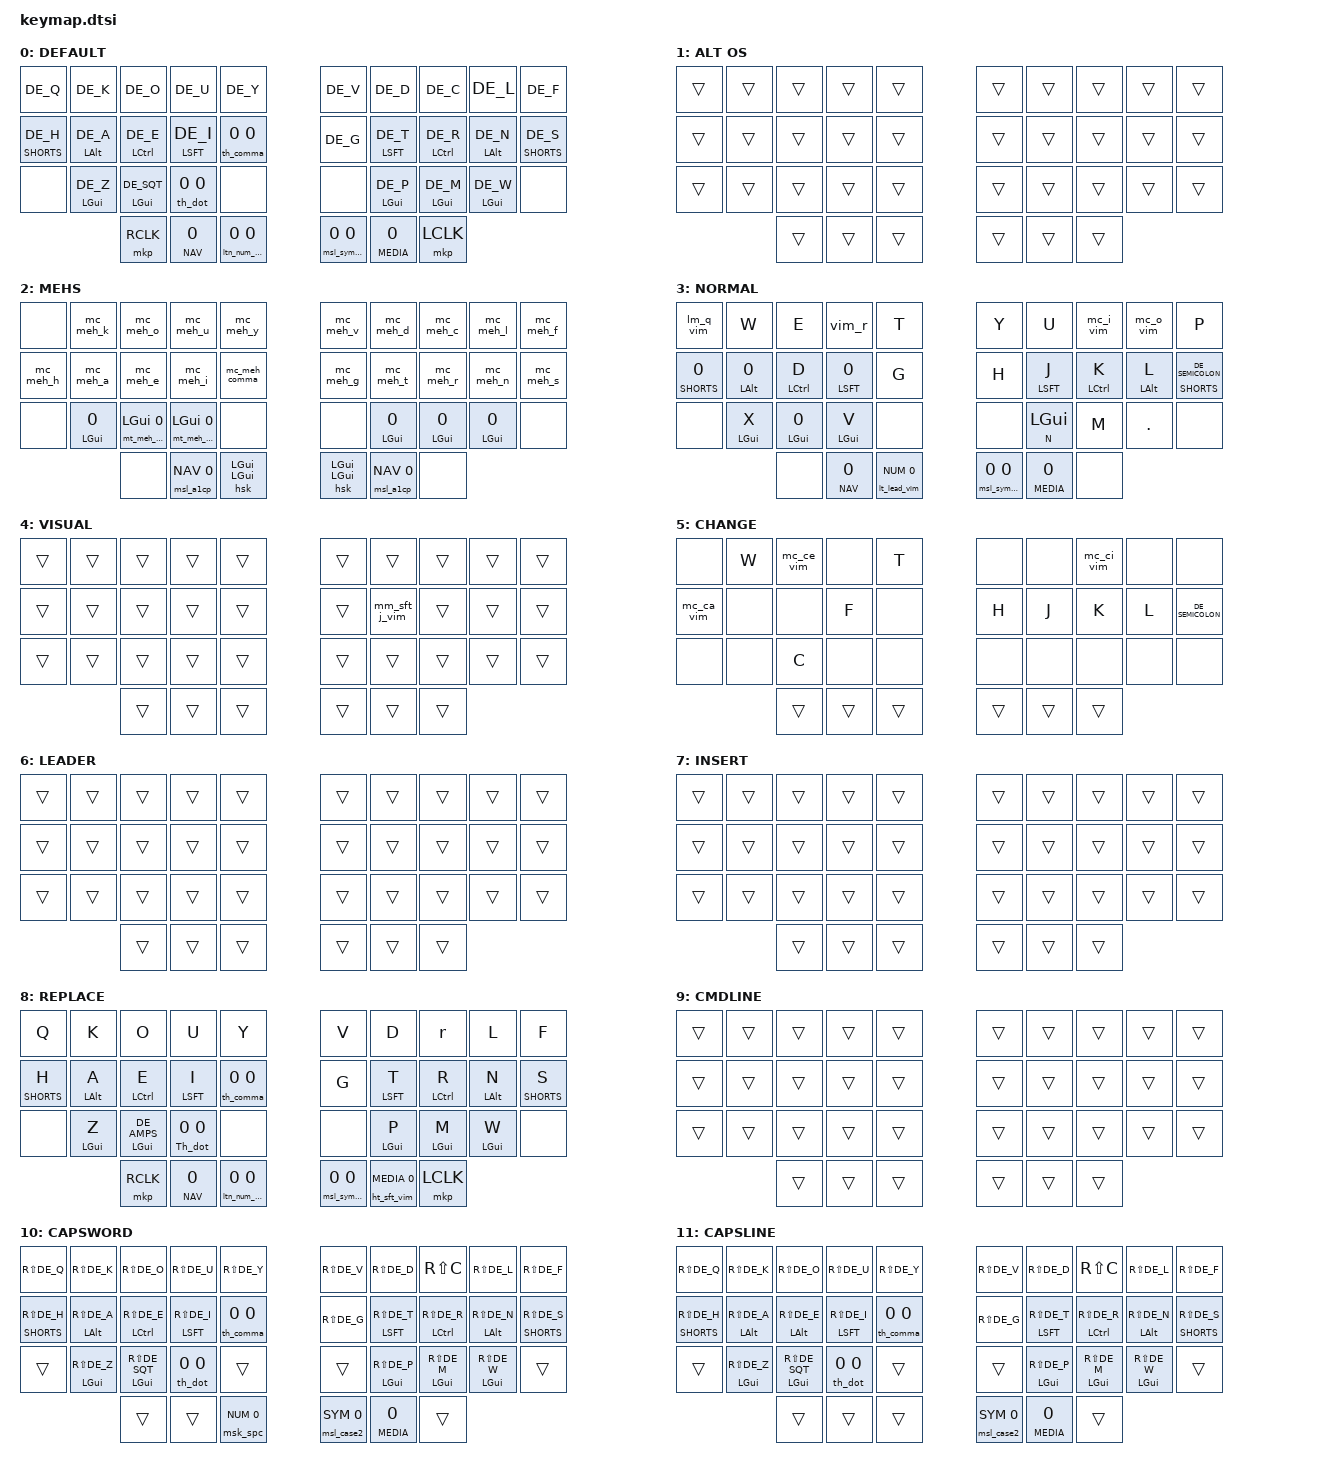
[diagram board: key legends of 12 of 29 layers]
/*
*
* Copyright (c) 2022 Rafael Romão
* SPDX-License-Identifier: MIT
*
*/

#include "includes.h"

/ {
        keymap {
                compatible = "zmk,keymap";

                default_layer {
                     display-name = "DEFAULT";
                     bindings = <
   &kp DE_Q            &kp DE_K            &kp DE_O            &kp DE_U            &kp DE_Y            &kp DE_V            &kp DE_D            &kp DE_C            &kp DE_L           &kp DE_F
   &lt SHORTS DE_H     &mt LALT DE_A       &mt LCTL DE_E       &mt LSFT DE_I       &th_comma 0 0       &kp DE_G            &mt LSFT DE_T       &mt LCTL DE_R       &mt LALT DE_N      &lt SHORTS DE_S
   &none               &mt LGUI DE_Z       &mt LGUI DE_SQT     &th_dot 0 0         &none               &none               &mt LGUI DE_P       &mt LGUI DE_M       &mt LGUI DE_W      &none
                                           &mkp RCLK           &ht_repeat NAV 0    &ltn_num_spc 0 0    &msl_sym_a2 0 0     &ht_shift MEDIA 0   &mkp LCLK
                        >;
                };

                alt_os_layer {
                     display-name = "ALT OS";
                     bindings = <
   &trans              &trans              &trans              &trans              &trans              &trans              &trans              &trans              &trans              &trans
   &trans              &trans              &trans              &trans              &trans              &trans              &trans              &trans              &trans              &trans
   &trans              &trans              &trans              &trans              &trans              &trans              &trans              &trans              &trans              &trans
                                           &trans              &trans              &trans              &trans              &trans              &trans
                        >;
                };


                mehs_layer {
                     display-name = "MEHS";
                     bindings = <
   &none              &mc_meh_k            &mc_meh_o           &mc_meh_u           &mc_meh_y           &mc_meh_v           &mc_meh_d           &mc_meh_c           &mc_meh_l           &mc_meh_f
   &mc_meh_h          &mc_meh_a            &mc_meh_e           &mc_meh_i           &mc_meh_comma       &mc_meh_g           &mc_meh_t           &mc_meh_r           &mc_meh_n           &mc_meh_s
   &none              &mt_meh_z LGUI 0     &mt_meh_sqt LGUI 0  &mt_meh_dot LGUI 0  &none               &none               &mt_meh_p LGUI 0    &mt_meh_m LGUI 0    &mt_meh_w LGUI 0    &none
                                           &none               &msl_a1cp NAV 0     &hsk LGUI LGUI      &hsk LGUI LGUI      &msl_a1cp NAV 0     &none
                        >;
                };


                vim_normal_layer {
                     display-name = "NORMAL";
                     bindings = <
   &lm_q_vim           &kp W               &kp E               &vim_r              &kp T               &kp Y               &kp U               &mc_i_vim           &mc_o_vim           &kp P
   &lt_a_vim SHORTS 0  &mt_s_vim LALT 0    &mt LCTL D          &mt_f_vim LSFT 0    &kp G               &kp H               &mt LSFT J          &mt LCTL K          &mt LALT L          &lt SHORTS DE_SEMICOLON
   &none               &mt LGUI X          &mt_c_vim LGUI 0    &mt LGUI V          &none               &none               &mt N LGUI 0        &kp M               &kp DOT             &none
                                           &none               &ht_repeat NAV 0    &lt_lead_vim NUM 0  &msl_sym_a2 0 0     &ht_shift MEDIA 0   &none
                        >;
                };

                vim_visual_layer {
                     display-name = "VISUAL";
                     bindings = <
   &trans              &trans              &trans              &trans              &trans              &trans              &trans              &trans              &trans              &trans
   &trans              &trans              &trans              &trans              &trans              &trans              &mm_sft_j_vim       &trans              &trans              &trans
   &trans              &trans              &trans              &trans              &trans              &trans              &trans              &trans              &trans              &trans
                                           &trans              &trans              &trans              &trans              &trans              &trans
                        >;
                };

                vim_change_layer {
                     display-name = "CHANGE";
                     bindings = <
   &none               &kp W               &mc_ce_vim          &none               &kp T               &none               &none               &mc_ci_vim          &none               &none
   &mc_ca_vim          &none               &none               &kp F               &none               &kp H               &kp J               &kp K               &kp L               &kp DE_SEMICOLON
   &none               &none               &kp C               &none               &none               &none               &none               &none               &none               &none
                                           &trans              &trans              &trans              &trans              &trans              &trans
                        >;
                };

                vim_leader_layer {
                     display-name = "LEADER";
                     bindings = <
   &trans              &trans              &trans              &trans              &trans              &trans              &trans              &trans              &trans              &trans
   &trans              &trans              &trans              &trans              &trans              &trans              &trans              &trans              &trans              &trans
   &trans              &trans              &trans              &trans              &trans              &trans              &trans              &trans              &trans              &trans
                                           &trans              &trans              &trans              &trans              &trans              &trans
                        >;
                };

                vim_insert_layer {
                     display-name = "INSERT";
                     bindings = <
   &trans              &trans              &trans              &trans              &trans              &trans              &trans              &trans              &trans              &trans
   &trans              &trans              &trans              &trans              &trans              &trans              &trans              &trans              &trans              &trans
   &trans              &trans              &trans              &trans              &trans              &trans              &trans              &trans              &trans              &trans
                                           &trans              &trans              &trans              &trans              &trans              &trans
                        >;
                };

                vim_replace_layer {
                     display-name = "REPLACE";
                     bindings = <
   &kp Q               &kp K               &kp O               &kp U               &kp Y               &kp V               &kp D               &kp r               &kp L               &kp F
   &lt SHORTS H        &mt LALT A          &mt LCTL E          &mt LSFT I          &th_comma 0 0       &kp G               &mt LSFT T          &mt LCTL R          &mt LALT N          &lt SHORTS S
   &none               &mt LGUI Z          &mt LGUI DE_AMPS    &Th_dot 0 0         &none               &none               &mt LGUI P          &mt LGUI M          &mt LGUI W          &none
                                           &mkp RCLK           &ht_repeat NAV 0    &ltn_num_spc 0 0    &msl_sym_a2 0 0     &ht_sft_vim MEDIA 0 &mkp LCLK
                        >;
                };

                vim_cmdline_layer {
                     display-name = "CMDLINE";
                     bindings = <
   &trans              &trans              &trans              &trans              &trans              &trans              &trans              &trans              &trans              &trans
   &trans              &trans              &trans              &trans              &trans              &trans              &trans              &trans              &trans              &trans
   &trans              &trans              &trans              &trans              &trans              &trans              &trans              &trans              &trans              &trans
                                           &trans              &trans              &trans              &trans              &trans              &trans
                        >;
                };


                capsword_layer {
                     display-name = "CAPSWORD";
                     bindings = <
   &kp RS(DE_Q)        &kp RS(DE_K)        &kp RS(DE_O)        &kp RS(DE_U)        &kp RS(DE_Y)        &kp RS(DE_V)        &kp RS(DE_D)        &kp RS(C)           &kp RS(DE_L)        &kp RS(DE_F)
   &lt SHORTS RS(DE_H) &mt LALT RS(DE_A)   &mt LCTL RS(DE_E)   &mt LSFT RS(DE_I)   &th_comma 0 0       &kp RS(DE_G)        &mt LSFT RS(DE_T)   &mt LCTL RS(DE_R)   &mt LALT RS(DE_N)   &lt SHORTS RS(DE_S)
   &trans              &mt LGUI RS(DE_Z)   &mt LGUI RS(DE_SQT) &th_dot 0 0         &trans              &trans              &mt LGUI RS(DE_P)   &mt LGUI RS(DE_M)   &mt LGUI RS(DE_W)   &trans
                                           &trans              &trans              &msk_spc NUM 0      &msl_case2 SYM 0    &lt_cancel MEDIA 0  &trans
                        >;
                };
                capsline_layer {
                     display-name = "CAPSLINE";
                     bindings = <
   &kp RS(DE_Q)        &kp RS(DE_K)        &kp RS(DE_O)        &kp RS(DE_U)        &kp RS(DE_Y)        &kp RS(DE_V)        &kp RS(DE_D)        &kp RS(C)           &kp RS(DE_L)        &kp RS(DE_F)
   &lt SHORTS RS(DE_H) &mt LALT RS(DE_A)   &mt LALT RS(DE_E)   &mt LSFT RS(DE_I)   &th_comma 0 0       &kp RS(DE_G)        &mt LSFT RS(DE_T)   &mt LCTL RS(DE_R)   &mt LALT RS(DE_N)   &lt SHORTS RS(DE_S)
   &trans              &mt LGUI RS(DE_Z)   &mt LGUI RS(DE_SQT) &th_dot 0 0         &trans              &trans              &mt LGUI RS(DE_P)   &mt LGUI RS(DE_M)   &mt LGUI RS(DE_W)   &trans
                                           &trans              &trans              &trans              &msl_case2 SYM 0    &lt_cancel MEDIA 0  &trans
                        >;
                };

                alpha2_layer {
                     display-name = "ALPHA2";
                     bindings = <
   &none               &none               &kp DE_O_UMLAUT     &kp DE_U_UMLAUT     &none               &none               &kp DE_SZ           &kp DE_SZ           &none               &none
   &none               &kp DE_A_UMLAUT     &kp DE_A_UMLAUT     &kp DE_O_UMLAUT     &none               &none               &kp DE_B            &kp DE_J            &none               &none
   &none               &none               &kp DE_X            &kp DE_X            &none               &none               &none               &none               &none               &none
                                           &none               &mc_sqo             &kp DE_UNDER        &kp DE_SPACE        &mc_sqo             &none
                        >;
                };

                numbers_layer {
                     display-name = "NUMBERS";
                     bindings = <
   &none               &th_lbrc 0 0        &th_rbrc 0 0        &kp DE_BSLH         &none               &none               &mc_n7              &mc_n8              &mc_n9              &none
   &lt_deg FUN 0       &th_lpar 0 0        &th_rpar 0 0        &kp DE_AMPS         &none               &none               &mc_n4              &mc_n5              &mc_n6              &kp DE_DOT
   &none               &th_lbkt 0 0        &th_rbkt 0 0        &kp DE_PIPE         &none               &none               &mc_n1              &mc_n2              &mc_n3              &none
                                           &none               &trans              &trans              &hlt SYM SPACE      &lt_n0 MEDIA 0      &none 
                        >;
                };
                symbols_layer {
                     display-name = "SYMBOLS";
                     bindings = <
   &none               &mc_tilde           &kp DE_HASH         &th_sqo 0 0         &none               &none               &th_perc 0 0        &th_eql 0 0         &th_colon_vim 0 0   &none
   &kp DE_AT           &th_caret_z 0 0     &kp DE_DOLLAR       &th_dqo 0 0         &none               &none               &th_qmark 0 0       &kp DE_MINUS        &kp DE_PLUS         &lt MACROS DE_COMMA
   &none               &mc_lt              &mc_gt              &th_bti 0 0         &none               &none               &th_excl 0 0        &vim_slash          &kp DE_STAR         &none
                                           &none               &trans              &hlt NUM_CP SPACE   &none               &trans              &none
                        >;
                };

                sentence_case_layer {
                     display-name = "SENTENCE CASE";
                     bindings = <
   &kp LS(DE_Q)        &kp LS(DE_K)        &kp LS(DE_O)        &kp LS(DE_U)        &kp LS(DE_Y)        &kp LS(DE_V)        &kp LS(DE_D)        &kp LS(DE_C)        &kp LS(DE_L)        &kp LS(DE_F)
   &kp LS(DE_H)        &mt LALT LS(DE_A)   &mt LCTL LS(DE_E)   &mt LSFT LS(DE_I)   &th_comma           &kp LS(DE_G)        &mt LSFT LS(DE_T)   &mt LCTL LS(DE_R)   &mt LALT LS(DE_N)   &kp LS(DE_S)
   &none               &mt LGUI LS(DE_Z)   &mt LGUI LS(DE_SQT) &th_dot 0 0         &none               &none               &mt LGUI LS(DE_P)   &mt LGUI LS(DE_M)   &mt LGUI LS(DE_W)   &trans
                                           &trans              &trans              &trans              &lt_sft_a2 SYM_CP 0 &trans              &trans
                        >;
                };

                shifted_alpha2_layer {
                     display-name = "SHIFTED ALPHA2";
                     bindings = <
   &none               &none               &kp LS(DE_O_UMLAUT) &kp LS(DE_U_UMLAUT) &none               &none               &kp LS(DE_SZ)       &none               &none               &none
   &none               &kp LS(DE_A_UMLAUT) &kp LS(DE_A_UMLAUT) &kp LS(DE_O_UMLAUT) &none               &none               &kp LS(DE_B)        &kp LS(DE_J)        &none               &none
   &none               &none               &none               &kp LS(DE_X)        &none               &none               &none               &none               &none               &none
                                           &none               &mc_sqo             &trans              &kp SPACE           &mc_sqo             &none 
                        >;
                };
                case_alpha2_layer {
                     display-name = "CASE ALPHA2";
                     bindings = <
   &none               &kp RS(Q)           &kp RS(DE_O_UMLAUT) &kp RS(DE_U_UMLAUT) &none               &none               &ac_ocir_c          &ac_oacu_c          &ac_uacu_c          &none
   &none               &kp RS(DE_A_UMLAUT) &kp RS(DE_SHARP_S)  &kp RS(DE_X)        &none               &none               &ac_atil_c          &ac_aacu_c          &ac_eacu_c          &ac_iacu_c
   &none               &none               &none               &reversed_magic_c   &none               &none               &ac_otil_c          &ac_acir_c          &ac_ecir_c          &none
                                           &none               &mc_sqo             &kp DE_UNDER        &kp SPACE           &mc_sqo             &none
                        >;
                };

                shortcuts_layer {
                     display-name = "SHORTCUTS";
                     bindings = <
   &none              &mc_calc             &mc_files           &mc_browser         &none               &none               &mc_ai              &mc_editor          &mc_activities      &none
   &mc_leader         &lt_zoom_out TOGS 0  &mc_zoom_in         &mc_new             &none               &none               &tc_num_word        &mc_containers      &lt_emoji TOGS 0    &mc_leader
   &none              &mc_close            &mc_refresh         &mc_reopen          &none               &none               &mc_screenshot      &mc_notes           &mc_term            &none
                                           &none               &mo TEXT            &lt FUN SPACE       &lt MACROS SPACE    &mo TEXT            &none 
                        >;
                };
                toggles_layer {
                     display-name = "TOGGLES";
                     bindings = <
   &none              &none                &bt BT_SEL 0        &bt BT_CLR          &none               &none               &to NAV             &to FUN             &none               &none
   &none              &none                &bt BT_PRV          &bt BT_NXT          &none               &none               &to NUM             &to MEDIA           &none               &none
   &none              &bootloader          &tog_off ALT_OS     &to ALT_OS          &none               &none               &to VIM_NORMAL      &to MEHS            &bootloader         &none
                                           &none               &kp CAPS            &kp KP_NUM          &mc_lock            &mc_sleep           &none
                        >;
                };

                secondary_alternate_repeat_layer {
                     display-name = "ALT REP 2";
                     bindings = <
   &trans              &trans              &trans              &trans              &trans              &trans              &trans              &trans              &trans              &trans
   &trans              &trans              &trans              &trans              &trans              &trans              &trans              &trans              &trans              &trans
   &trans              &trans              &trans              &trans              &trans              &trans              &trans              &trans              &trans              &trans
                                           &trans              &ht_alt_rep NAV 0   &trans              &trans              &trans              &trans
                        >;
                };

                navigation_layer {
                     display-name = "NAVIGATION";
                     bindings = <
   &none               &mc_swapper         &mc_tabs            &mc_launcher        &none               &none               &kp TAB             &lm_ent_vim         &lm_esc_vim         &none
   &lt_system TEXT 0   &mod_num LALT LALT  &mod_num LCTL LCTL  &mod_num LSFT LSFT  &none               &none               &kp LEFT            &kp DOWN            &kp UP              &kp RIGHT
   &none               &mod_num LGUI LGUI  &mod_num LGUI LGUI  &mod_num LGUI LGUI  &none               &none               &kp DEL             &kp HOME            &kp END             &none
                                           &none               &trans              &none               &hlt SYM_CP SPACE   &lt MEDIA INS       &none
                        >;
                };

                numbers_copy_layer {
                     display-name = "NUMBERS";
                     bindings = <
   &none               &th_lbrc 0 0        &th_rbrc 0 0        &kp DE_BSLH         &none               &none               &mc_n7              &mc_n8              &mc_n9              &none
   &mc_deg             &th_lpar 0 0        &th_rpar 0 0        &kp DE_AMPS         &none               &none               &mc_n4              &mc_n5              &mc_n6              &kp DE_DOT
   &none               &th_lbkt 0 0        &th_rbkt 0 0        &kp DE_PIPE         &none               &none               &mc_n1              &mc_n2              &mc_n3              &none
                                           &none               &trans              &trans              &hlt SYM_CP SPACE   &lt_n0 MEDIA 0      &none
                        >;
                };
                symbols_copy_layer {
                     display-name = "SYMBOLS";
                     bindings = <
   &none               &mc_tilde           &kp DE_HASH         &th_sqo 0 0         &none               &none               &th_perc 0 0        &th_eql 0 0         &th_colon_vim 0 0      &none
   &kp DE_AT           &th_caret_z 0 0     &kp DE_DOLLAR       &th_dqo 0 0         &none               &none               &th_qmark 0 0       &kp DE_MINUS        &kp DE_PLUS            &kp DE_STAR
   &none               &mc_lt              &mc_gt              &th_bti 0 0         &none               &none               &th_excl 0 0        &kp DE_SLASH        &kp DE_STAR            &none
                                           &none               &trans              &kp SPACE           &kp SPACE           &trans              &none 
                        >;
                };

                media_layer {
                    display-name = "MOUSE";
                    bindings = <
   &none               &msc SCRL_DOWN      &mmv MOVE_UP        &msc SCRL_UP        &none               &none               &mc_home_tab        &mc_end_enter_vim   &lm_esc_vim        &none
   &none               &mmv MOVE_LEFT      &mmv MOVE_DOWN      &mmv MOVE_RIGHT     &none               &none               &mc_mic             &mt C_MUTE C_VOL_DN &kp C_VOL_UP       &lt_cam TEXT 0
   &none               &mkc RCTL           &mmv MOVE_DOWN      &mkp LCTL           &none               &none               &kp C_Prev          &kp C_PP            &kp C_NEXT         &none
                                           &none               &mo NAV_CP          &kp SPACE           &none               &trans              &none
                        >;
                };
                navigation_copy_layer {
                     display-name = "NAVIGATION";
                     bindings = <
   &none               &mc_swapper         &mc_tabs            &mc_launcher        &none               &none               &kp TAB             &lm_ent_vim         &lm_esc_vim        &none
   &mc_system          &kp LALT            &kp LCTL            &kp LSFT            &none               &none               &kp LEFT            &kp DOWN            &kp UP             &kp RIGHT
   &none               &kp LGUI            &kp LGUI            &kp LGUI            &none               &none               &kp DEL             &kp HOME            &kp END            &none 
                                           &none               &trans              &trans              &trans              &kp INS             &none 
                        >;
                };

                text_layer {
                     display-name = "TEXT NAVIGATION";
                     bindings = <
   &none               &select_home        &select_word        &select_line        &trans              &trans              &kp TAB             &lm_ent_vim         &lm_esc_vim        &none
   &none               &kp LALT            &kp LCTL            &kp LSFT            &trans              &trans              &mc_prev_word       &kp DOWN            &kp UP             &mc_next_word
   &none               &kp LGUI            &kp LGUI            &kp LGUI            &trans              &trans              &mc_del_word        &kp HOME            &kp END            &none
                                           &none               &none               &none               &none               &none               &none
                        >;
                };
                functions_layer {
                     display-name = "FUNCTIONS";
                     bindings = <
   &none               &kp F13             &kp F14             &kp F15             &none               &none               &kp F7              &kp F8              &kp F9             &none
   &none               &hsk LALT LALT      &hsk LCTL LCTL      &hsk LSFT LSFT      &none               &none               &kp F4              &kp F5              &kp F6             &kp F12
   &none               &hsk LGUI LGUI      &hsk LGUI LGUI      &hsk LGUI LGUI      &none               &none               &kp F1              &kp F2              &kp F3             &none
                                           &none               &none               &none               &kp F10             &kp F11             &none
                        >;
                };


                macros_layer {
                     display-name = "MACROS";
                     bindings = <
   &none               &mc_tisl            &mc_ds              &mc_dds             &none               &none               &mc_colpercsslash   &mc_o_esc           &mc_sft_o_esc     &none
   &mc_exit            &mc_hugs            &mc_oref            &mc_otask           &none               &none               &lm_sft_v_vim       &mc_dqt0p           &mc_dqt1p         &none
   &none               &lm_os              &mc_comment         &mc_haha            &none               &none               &lm_ctl_v_vim       &mc_dqtplusp        &mc_dqtplusy      &none
                                           &none               &none               &mc_spc_esc         &none               &none               &none
                        >;
                };


        };
};
